AUTOSAR XML (schema 4-2-2)
package /APTIV_MODEL_APP/ComponentType
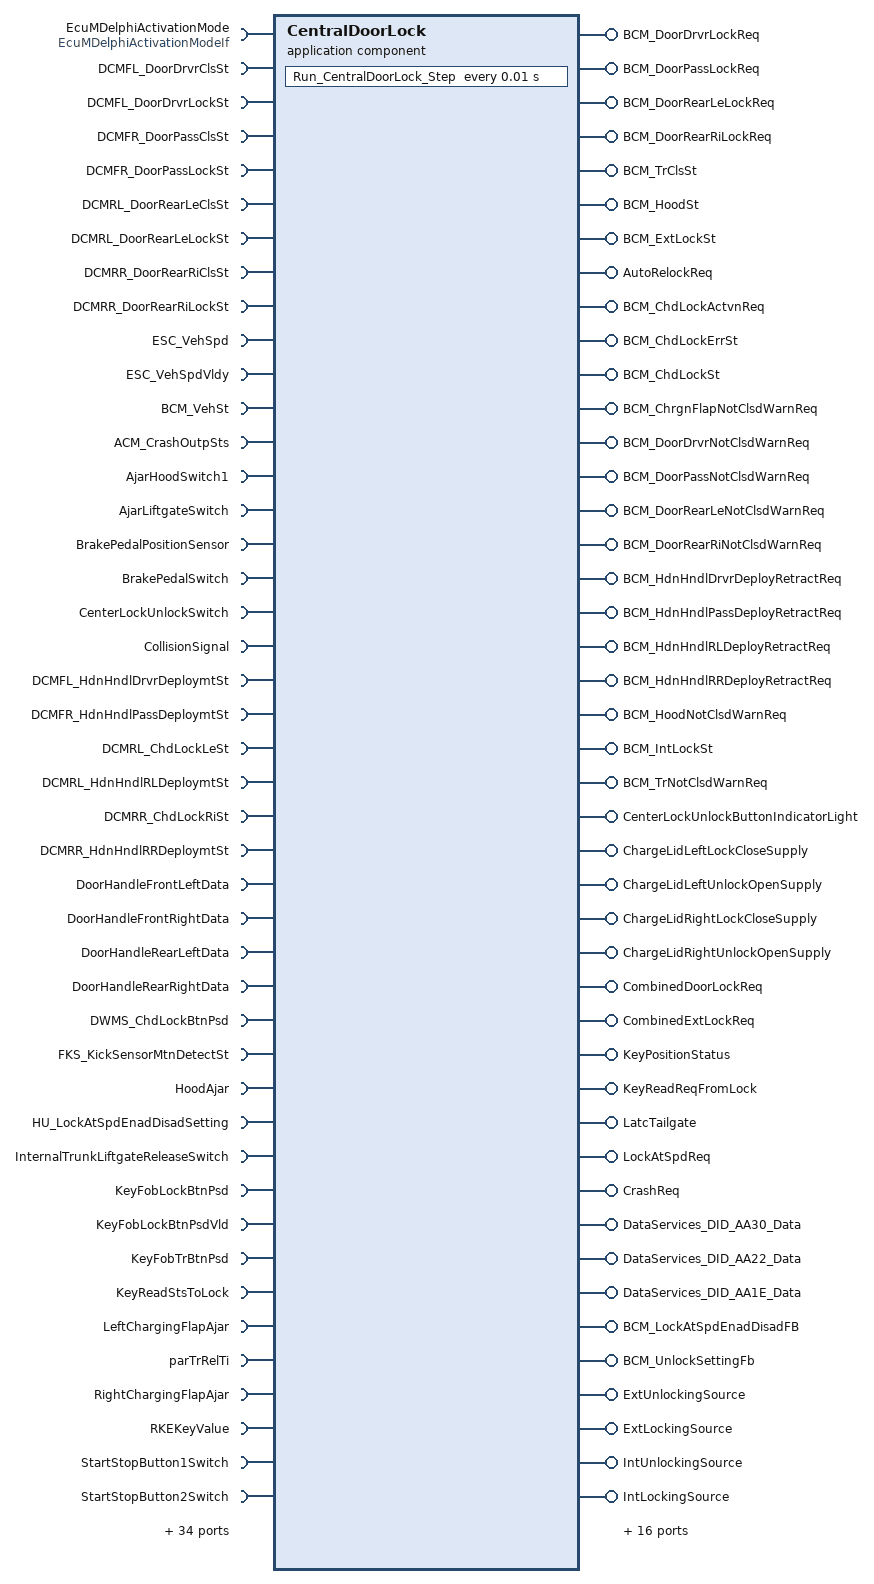
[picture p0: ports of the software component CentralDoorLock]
  application sw component type CentralDoorLock
    12 x require port:
      EcuMDelphiActivationMode: mode-switch-receiver-com-spec=supports-asynchronous-mode-switch=false, required-interface=EcuMDelphiActivationModeIf
      DCMFL_DoorDrvrClsSt: nonqueued-receiver-com-spec{data-element=DCMFL_DoorDrvrClsSt, init-value=constant-reference=Temp_InitValue}, required-interface=DCMFL_DoorDrvrClsSt
      DCMFL_DoorDrvrLockSt: nonqueued-receiver-com-spec{data-element=DCMFL_DoorDrvrLockSt, init-value=constant-reference=Temp_InitValue}, required-interface=DCMFL_DoorDrvrLockSt
      DCMFR_DoorPassClsSt: nonqueued-receiver-com-spec{data-element=DCMFR_DoorPassClsSt, init-value=constant-reference=Temp_InitValue}, required-interface=DCMFR_DoorPassClsSt
      DCMFR_DoorPassLockSt: nonqueued-receiver-com-spec{data-element=DCMFR_DoorPassLockSt, init-value=constant-reference=Temp_InitValue}, required-interface=DCMFR_DoorPassLockSt
      DCMRL_DoorRearLeClsSt: nonqueued-receiver-com-spec{data-element=DCMRL_DoorRearLeClsSt, init-value=constant-reference=Temp_InitValue}, required-interface=DCMRL_DoorRearLeClsSt
      DCMRL_DoorRearLeLockSt: nonqueued-receiver-com-spec{data-element=DCMRL_DoorRearLeLockSt, init-value=constant-reference=Temp_InitValue}, required-interface=DCMRL_DoorRearLeLockSt
      DCMRR_DoorRearRiClsSt: nonqueued-receiver-com-spec{data-element=DCMRR_DoorRearRiClsSt, init-value=constant-reference=Temp_InitValue}, required-interface=DCMRR_DoorRearRiClsSt
      DCMRR_DoorRearRiLockSt: nonqueued-receiver-com-spec{data-element=DCMRR_DoorRearRiLockSt, init-value=constant-reference=Temp_InitValue}, required-interface=DCMRR_DoorRearRiLockSt
      ESC_VehSpd: nonqueued-receiver-com-spec{data-element=ESC_VehSpd, init-value=constant-reference=Temp_InitValue}, required-interface=ESC_VehSpd
      ESC_VehSpdVldy: nonqueued-receiver-com-spec{data-element=ESC_VehSpdVldy, init-value=constant-reference=Temp_InitValue}, required-interface=ESC_VehSpdVldy
      BCM_VehSt: nonqueued-receiver-com-spec{data-element=BCM_VehSt, init-value=constant-reference=Temp_InitValue}, required-interface=BCM_VehSt
    7 x provide port:
      BCM_DoorDrvrLockReq: nonqueued-sender-com-spec{data-element=BCM_DoorDrvrLockReq, init-value=constant-reference=Temp_InitValue}, provided-interface=BCM_DoorDrvrLockReq
      BCM_DoorPassLockReq: nonqueued-sender-com-spec{data-element=BCM_DoorPassLockReq, init-value=constant-reference=Temp_InitValue}, provided-interface=BCM_DoorPassLockReq
      BCM_DoorRearLeLockReq: nonqueued-sender-com-spec{data-element=BCM_DoorRearLeLockReq, init-value=constant-reference=Temp_InitValue}, provided-interface=BCM_DoorRearLeLockReq
      BCM_DoorRearRiLockReq: nonqueued-sender-com-spec{data-element=BCM_DoorRearRiLockReq, init-value=constant-reference=Temp_InitValue}, provided-interface=BCM_DoorRearRiLockReq
      BCM_TrClsSt: nonqueued-sender-com-spec{data-element=BCM_TrClsSt, init-value=constant-reference=Temp_InitValue}, provided-interface=BCM_TrClsSt
      BCM_HoodSt: nonqueued-sender-com-spec{data-element=BCM_HoodSt, init-value=constant-reference=Temp_InitValue}, provided-interface=BCM_HoodSt
      BCM_ExtLockSt: nonqueued-sender-com-spec{data-element=BCM_ExtLockSt, init-value=constant-reference=Temp_InitValue}, provided-interface=BCM_ExtLockSt
    35 x require port:
      ACM_CrashOutpSts: nonqueued-receiver-com-spec{data-element=ACM_CrashOutpSts, init-value=constant-reference=Temp_InitValue}, required-interface=ACM_CrashOutpSts
      AjarHoodSwitch1: nonqueued-receiver-com-spec{data-element=AjarHoodSwitch1, init-value=constant-reference=Temp_InitValue}, required-interface=AjarHoodSwitch1
      AjarLiftgateSwitch: nonqueued-receiver-com-spec{data-element=AjarLiftgateSwitch, init-value=constant-reference=Temp_InitValue}, required-interface=AjarLiftgateSwitch
      BrakePedalPositionSensor: nonqueued-receiver-com-spec{data-element=BrakePedalPositionSensor, init-value=constant-reference=Temp_InitValue}, required-interface=BrakePedalPositionSensor
      BrakePedalSwitch: nonqueued-receiver-com-spec{data-element=BrakePedalSwitch, init-value=constant-reference=Temp_InitValue}, required-interface=BrakePedalSwitch
      CenterLockUnlockSwitch: nonqueued-receiver-com-spec{data-element=CenterLockUnlockSwitch, init-value=constant-reference=Temp_InitValue}, required-interface=CenterLockUnlockSwitch
      CollisionSignal: nonqueued-receiver-com-spec{data-element=CollisionSignal, init-value=constant-reference=Temp_InitValue}, required-interface=CollisionSignal
      DCMFL_HdnHndlDrvrDeploymtSt: nonqueued-receiver-com-spec{data-element=DCMFL_HdnHndlDrvrDeploymtSt, init-value=constant-reference=Temp_InitValue}, required-interface=DCMFL_HdnHndlDrvrDeploymtSt
      DCMFR_HdnHndlPassDeploymtSt: nonqueued-receiver-com-spec{data-element=DCMFR_HdnHndlPassDeploymtSt, init-value=constant-reference=Temp_InitValue}, required-interface=DCMFR_HdnHndlPassDeploymtSt
      DCMRL_ChdLockLeSt: nonqueued-receiver-com-spec{data-element=DCMRL_ChdLockLeSt, init-value=constant-reference=Temp_InitValue}, required-interface=DCMRL_ChdLockLeSt
      DCMRL_HdnHndlRLDeploymtSt: nonqueued-receiver-com-spec{data-element=DCMRL_HdnHndlRLDeploymtSt, init-value=constant-reference=Temp_InitValue}, required-interface=DCMRL_HdnHndlRLDeploymtSt
      DCMRR_ChdLockRiSt: nonqueued-receiver-com-spec{data-element=DCMRR_ChdLockRiSt, init-value=constant-reference=Temp_InitValue}, required-interface=DCMRR_ChdLockRiSt
      DCMRR_HdnHndlRRDeploymtSt: nonqueued-receiver-com-spec{data-element=DCMRR_HdnHndlRRDeploymtSt, init-value=constant-reference=Temp_InitValue}, required-interface=DCMRR_HdnHndlRRDeploymtSt
      DoorHandleFrontLeftData: nonqueued-receiver-com-spec{data-element=DoorHandleFrontLeftData, init-value=constant-reference=Temp_InitValue}, required-interface=DoorHandleFrontLeftData
      DoorHandleFrontRightData: nonqueued-receiver-com-spec{data-element=DoorHandleFrontRightData, init-value=constant-reference=Temp_InitValue}, required-interface=DoorHandleFrontRightData
      DoorHandleRearLeftData: nonqueued-receiver-com-spec{data-element=DoorHandleRearLeftData, init-value=constant-reference=Temp_InitValue}, required-interface=DoorHandleRearLeftData
      DoorHandleRearRightData: nonqueued-receiver-com-spec{data-element=DoorHandleRearRightData, init-value=constant-reference=Temp_InitValue}, required-interface=DoorHandleRearRightData
      DWMS_ChdLockBtnPsd: nonqueued-receiver-com-spec{data-element=DWMS_ChdLockBtnPsd, init-value=constant-reference=Temp_InitValue}, required-interface=DWMS_ChdLockBtnPsd
      FKS_KickSensorMtnDetectSt: nonqueued-receiver-com-spec{data-element=FKS_KickSensorMtnDetectSt, init-value=constant-reference=Temp_InitValue}, required-interface=FKS_KickSensorMtnDetectSt
      HoodAjar: nonqueued-receiver-com-spec{data-element=HoodAjar, init-value=constant-reference=Temp_InitValue}, required-interface=HoodAjar
      HU_LockAtSpdEnadDisadSetting: nonqueued-receiver-com-spec{data-element=HU_LockAtSpdEnadDisadSetting, enable-update=true, init-value=constant-reference=Temp_InitValue}, required-interface=HU_LockAtSpdEnadDisadSetting
      InternalTrunkLiftgateReleaseSwitch: nonqueued-receiver-com-spec{data-element=InternalTrunkLiftgateReleaseSwitch, init-value=constant-reference=Temp_InitValue}, required-interface=InternalTrunkLiftgateReleaseSwitch
      KeyFobLockBtnPsd: nonqueued-receiver-com-spec{data-element=KeyFobLockBtnPsd, init-value=constant-reference=Temp_InitValue}, required-interface=KeyFobLockBtnPsd
      KeyFobLockBtnPsdVld: nonqueued-receiver-com-spec{data-element=KeyFobLockBtnPsdVld, init-value=constant-reference=Temp_InitValue}, required-interface=KeyFobLockBtnPsdVld
      KeyFobTrBtnPsd: nonqueued-receiver-com-spec{data-element=KeyFobTrBtnPsd, init-value=constant-reference=Temp_InitValue}, required-interface=KeyFobTrBtnPsd
      KeyReadStsToLock: nonqueued-receiver-com-spec{data-element=KeyReadStsToLock, init-value=constant-reference=Temp_InitValue}, required-interface=KeyReadStsToLock
      LeftChargingFlapAjar: nonqueued-receiver-com-spec{data-element=LeftChargingFlapAjar, init-value=constant-reference=Temp_InitValue}, required-interface=LeftChargingFlapAjar
      parTrRelTi: nonqueued-receiver-com-spec{data-element=parTrRelTi, init-value=constant-reference=Temp_InitValue}, required-interface=parTrRelTi
      RightChargingFlapAjar: nonqueued-receiver-com-spec{data-element=RightChargingFlapAjar, init-value=constant-reference=Temp_InitValue}, required-interface=RightChargingFlapAjar
      RKEKeyValue: nonqueued-receiver-com-spec{data-element=RKEKeyValue, init-value=constant-reference=Temp_InitValue}, required-interface=RKEKeyValue
      StartStopButton1Switch: nonqueued-receiver-com-spec{data-element=StartStopButton1Switch, init-value=constant-reference=Temp_InitValue}, required-interface=StartStopButton1Switch
      StartStopButton2Switch: nonqueued-receiver-com-spec{data-element=StartStopButton2Switch, init-value=constant-reference=Temp_InitValue}, required-interface=StartStopButton2Switch
      TCM_TrClsSt_TCM: nonqueued-receiver-com-spec{data-element=TCM_TrClsSt_TCM, init-value=constant-reference=Temp_InitValue}, required-interface=TCM_TrClsSt_TCM
      TrunkReleaseSwitch: nonqueued-receiver-com-spec{data-element=TrunkReleaseSwitch, init-value=constant-reference=Temp_InitValue}, required-interface=TrunkReleaseSwitch
      VCU_LoglGearStsAct: nonqueued-receiver-com-spec{data-element=VCU_LoglGearStsAct, init-value=constant-reference=Temp_InitValue}, required-interface=VCU_LoglGearStsAct
    27 x provide port:
      AutoRelockReq: nonqueued-sender-com-spec{data-element=AutoRelockReq, init-value=constant-reference=Temp_InitValue}, provided-interface=AutoRelockReq
      BCM_ChdLockActvnReq: nonqueued-sender-com-spec{data-element=BCM_ChdLockActvnReq, init-value=constant-reference=Temp_InitValue}, provided-interface=BCM_ChdLockActvnReq
      BCM_ChdLockErrSt: nonqueued-sender-com-spec{data-element=BCM_ChdLockErrSt, init-value=constant-reference=Temp_InitValue}, provided-interface=BCM_ChdLockErrSt
      BCM_ChdLockSt: nonqueued-sender-com-spec{data-element=BCM_ChdLockSt, init-value=constant-reference=Temp_InitValue}, provided-interface=BCM_ChdLockSt
      BCM_ChrgnFlapNotClsdWarnReq: nonqueued-sender-com-spec{data-element=BCM_ChrgnFlapNotClsdWarnReq, init-value=constant-reference=Temp_InitValue}, provided-interface=BCM_ChrgnFlapNotClsdWarnReq
      BCM_DoorDrvrNotClsdWarnReq: nonqueued-sender-com-spec{data-element=BCM_DoorDrvrNotClsdWarnReq, init-value=constant-reference=Temp_InitValue}, provided-interface=BCM_DoorDrvrNotClsdWarnReq
      BCM_DoorPassNotClsdWarnReq: nonqueued-sender-com-spec{data-element=BCM_DoorPassNotClsdWarnReq, init-value=constant-reference=Temp_InitValue}, provided-interface=BCM_DoorPassNotClsdWarnReq
      BCM_DoorRearLeNotClsdWarnReq: nonqueued-sender-com-spec{data-element=BCM_DoorRearLeNotClsdWarnReq, init-value=constant-reference=Temp_InitValue}, provided-interface=BCM_DoorRearLeNotClsdWarnReq
      BCM_DoorRearRiNotClsdWarnReq: nonqueued-sender-com-spec{data-element=BCM_DoorRearRiNotClsdWarnReq, init-value=constant-reference=Temp_InitValue}, provided-interface=BCM_DoorRearRiNotClsdWarnReq
      BCM_HdnHndlDrvrDeployRetractReq: nonqueued-sender-com-spec{data-element=BCM_HdnHndlDrvrDeployRetractReq, init-value=constant-reference=Temp_InitValue}, provided-interface=BCM_HdnHndlDrvrDeployRetractReq
      BCM_HdnHndlPassDeployRetractReq: nonqueued-sender-com-spec{data-element=BCM_HdnHndlPassDeployRetractReq, init-value=constant-reference=Temp_InitValue}, provided-interface=BCM_HdnHndlPassDeployRetractReq
      BCM_HdnHndlRLDeployRetractReq: nonqueued-sender-com-spec{data-element=BCM_HdnHndlRLDeployRetractReq, init-value=constant-reference=Temp_InitValue}, provided-interface=BCM_HdnHndlRLDeployRetractReq
      BCM_HdnHndlRRDeployRetractReq: nonqueued-sender-com-spec{data-element=BCM_HdnHndlRRDeployRetractReq, init-value=constant-reference=Temp_InitValue}, provided-interface=BCM_HdnHndlRRDeployRetractReq
      BCM_HoodNotClsdWarnReq: nonqueued-sender-com-spec{data-element=BCM_HoodNotClsdWarnReq, init-value=constant-reference=Temp_InitValue}, provided-interface=BCM_HoodNotClsdWarnReq
      BCM_IntLockSt: nonqueued-sender-com-spec{data-element=BCM_IntLockSt, init-value=constant-reference=Temp_InitValue}, provided-interface=BCM_IntLockSt
      BCM_TrNotClsdWarnReq: nonqueued-sender-com-spec{data-element=BCM_TrNotClsdWarnReq, init-value=constant-reference=Temp_InitValue}, provided-interface=BCM_TrNotClsdWarnReq
      CenterLockUnlockButtonIndicatorLight: nonqueued-sender-com-spec{data-element=CenterLockUnlockButtonIndicatorLight, init-value=constant-reference=Temp_InitValue}, provided-interface=CenterLockUnlockButtonIndicatorLight
      ChargeLidLeftLockCloseSupply: nonqueued-sender-com-spec{data-element=ChargeLidLeftLockCloseSupply, init-value=constant-reference=Temp_InitValue}, provided-interface=ChargeLidLeftLockCloseSupply
      ChargeLidLeftUnlockOpenSupply: nonqueued-sender-com-spec{data-element=ChargeLidLeftUnlockOpenSupply, init-value=constant-reference=Temp_InitValue}, provided-interface=ChargeLidLeftUnlockOpenSupply
      ChargeLidRightLockCloseSupply: nonqueued-sender-com-spec{data-element=ChargeLidRightLockCloseSupply, init-value=constant-reference=Temp_InitValue}, provided-interface=ChargeLidRightLockCloseSupply
      ChargeLidRightUnlockOpenSupply: nonqueued-sender-com-spec{data-element=ChargeLidRightUnlockOpenSupply, init-value=constant-reference=Temp_InitValue}, provided-interface=ChargeLidRightUnlockOpenSupply
      CombinedDoorLockReq: nonqueued-sender-com-spec{data-element=CombinedDoorLockReq, init-value=constant-reference=Temp_InitValue}, provided-interface=CombinedDoorLockReq
      CombinedExtLockReq: nonqueued-sender-com-spec{data-element=CombinedExtLockReq, init-value=constant-reference=Temp_InitValue}, provided-interface=CombinedExtLockReq
      KeyPositionStatus: nonqueued-sender-com-spec{data-element=KeyPositionStatus, init-value=constant-reference=Temp_InitValue}, provided-interface=KeyPositionStatus
      KeyReadReqFromLock: nonqueued-sender-com-spec{data-element=KeyReadReqFromLock, init-value=constant-reference=Temp_InitValue}, provided-interface=KeyReadReqFromLock
      LatcTailgate: nonqueued-sender-com-spec{data-element=LatcTailgate, init-value=constant-reference=Temp_InitValue}, provided-interface=LatcTailgate
      LockAtSpdReq: nonqueued-sender-com-spec{data-element=LockAtSpdReq, init-value=constant-reference=Temp_InitValue}, provided-interface=LockAtSpdReq
    require port CarCfgIntDistbn: required-interface=CarCfgIntDistbn
      required-com-specs:
        data-element=CarCfg232, init-value=constant-reference=Temp_InitValue
        data-element=CarCfg238, init-value=constant-reference=Temp_InitValue
        data-element=CarCfg319, init-value=constant-reference=Temp_InitValue
        data-element=CarCfg326, init-value=constant-reference=Temp_InitValue
    4 x provide port:
      CrashReq: nonqueued-sender-com-spec{data-element=CrashReq, init-value=constant-reference=Temp_InitValue}, provided-interface=CrashReq
      DataServices_DID_AA30_Data: provided-interface=DataServices_DID_AA30_Data
      DataServices_DID_AA22_Data: provided-interface=DataServices_DID_AA22_Data
      DataServices_DID_AA1E_Data: provided-interface=DataServices_DID_AA1E_Data
    25 x require port:
      TBOX_CloudLockUnlckReq: nonqueued-receiver-com-spec{data-element=TBOX_CloudLockUnlckReq, init-value=constant-reference=Temp_InitValue}, required-interface=TBOX_CloudLockUnlckReq
      TBOX_MobileAppLockUlckDoorReq: nonqueued-receiver-com-spec{data-element=TBOX_MobileAppLockUlckDoorReq, init-value=constant-reference=Temp_InitValue}, required-interface=TBOX_MobileAppLockUlckDoorReq
      ACM_RollovrCrashOutpSts: nonqueued-receiver-com-spec{data-element=ACM_RollovrCrashOutpSts, init-value=constant-reference=Temp_InitValue}, required-interface=ACM_RollovrCrashOutpSts
      BMS_HVBattThermRunaway: nonqueued-receiver-com-spec{data-element=BMS_HVBattThermRunaway, init-value=constant-reference=Temp_InitValue}, required-interface=BMS_HVBattThermRunaway
      HU_UnlockSetting: nonqueued-receiver-com-spec{data-element=HU_UnlockSetting, init-value=constant-reference=Temp_InitValue}, required-interface=HU_UnlockSetting
      NFC_NFCCardOutsideAuthentSt: nonqueued-receiver-com-spec{data-element=NFC_NFCCardOutsideAuthentSt, init-value=constant-reference=Temp_InitValue}, required-interface=NFC_NFCCardOutsideAuthentSt
      NFC_NFCCardOutsideRequest: nonqueued-receiver-com-spec{data-element=NFC_NFCCardOutsideRequest, init-value=constant-reference=Temp_InitValue}, required-interface=NFC_NFCCardOutsideRequest
      NFC_ImobNFCKeyAuthentSt: nonqueued-receiver-com-spec{data-element=NFC_ImobNFCKeyAuthentSt, init-value=constant-reference=Temp_InitValue}, required-interface=NFC_ImobNFCKeyAuthentSt
      HU_DCChrgnFlapRelReq: nonqueued-receiver-com-spec{data-element=HU_DCChrgnFlapRelReq, init-value=constant-reference=Temp_InitValue}, required-interface=HU_DCChrgnFlapRelReq
      HU_ACChrgnFlapRelReq: nonqueued-receiver-com-spec{data-element=HU_ACChrgnFlapRelReq, init-value=constant-reference=Temp_InitValue}, required-interface=HU_ACChrgnFlapRelReq
      HU_ChdLockSetting: nonqueued-receiver-com-spec{data-element=HU_ChdLockSetting, init-value=constant-reference=Temp_InitValue}, required-interface=HU_ChdLockSetting
      HU_ElecTrMaxOpenPossetting: nonqueued-receiver-com-spec{data-element=HU_ElecTrMaxOpenPossetting, init-value=constant-reference=Temp_InitValue}, required-interface=HU_ElecTrMaxOpenPossetting
      TCM_ElecTrMaxOpenPos: nonqueued-receiver-com-spec{data-element=TCM_ElecTrMaxOpenPos, init-value=constant-reference=Temp_InitValue}, required-interface=TCM_ElecTrMaxOpenPos
      HU_PepsAutoUnlockActSt: nonqueued-receiver-com-spec{data-element=HU_PepsAutoUnlockActSt, init-value=constant-reference=Temp_InitValue}, required-interface=HU_PepsAutoUnlockActSt
      HU_AutEclClsCfg: nonqueued-receiver-com-spec{data-element=HU_AutEclClsCfg, init-value=constant-reference=Temp_InitValue}, required-interface=HU_AutEclClsCfg
      HU_LockIndicatorSetting: nonqueued-receiver-com-spec{data-element=HU_LockIndicatorSetting, init-value=constant-reference=Temp_InitValue}, required-interface=HU_LockIndicatorSetting
      HU_ElecTrunkReq: nonqueued-receiver-com-spec{data-element=HU_ElecTrunkReq, init-value=constant-reference=Temp_InitValue}, required-interface=HU_ElecTrunkReq
      BCM_VehSecuAlrmSysSt: nonqueued-receiver-com-spec{data-element=BCM_VehSecuAlrmSysSt, init-value=constant-reference=Temp_InitValue}, required-interface=BCM_VehSecuAlrmSysSt
      ECL_EclActualPosition: nonqueued-receiver-com-spec{data-element=ECL_EclActualPosition, init-value=constant-reference=Temp_InitValue}, required-interface=ECL_EclActualPosition
      TBOX_MobileAppOpenClsChrgnLidReq: nonqueued-receiver-com-spec{data-element=TBOX_MobileAppOpenClsChrgnLidReq, init-value=constant-reference=Temp_InitValue}, required-interface=TBOX_MobileAppOpenClsChrgnLidReq
      IPU_ChrgAcCnctrDetd: nonqueued-receiver-com-spec{data-element=IPU_ChrgAcCnctrDetd, init-value=constant-reference=Temp_InitValue}, required-interface=IPU_ChrgAcCnctrDetd
      BMS_ChrgDcCnctrDetd: nonqueued-receiver-com-spec{data-element=BMS_ChrgDcCnctrDetd, init-value=constant-reference=Temp_InitValue}, required-interface=BMS_ChrgDcCnctrDetd
      TBOX_MobileAppOpenClsTrunkReq: nonqueued-receiver-com-spec{data-element=TBOX_MobileAppOpenClsTrunkReq, init-value=constant-reference=Temp_InitValue}, required-interface=TBOX_MobileAppOpenClsTrunkReq
      NFC_NFCCardInsideAuthentSt: nonqueued-receiver-com-spec{data-element=NFC_NFCCardInsideAuthentSt, init-value=constant-reference=Temp_InitValue}, required-interface=NFC_NFCCardInsideAuthentSt
      NFC_NFCCardInsideRequest: nonqueued-receiver-com-spec{data-element=NFC_NFCCardInsideRequest, init-value=constant-reference=Temp_InitValue}, required-interface=NFC_NFCCardInsideRequest
    20 x provide port:
      BCM_LockAtSpdEnadDisadFB: nonqueued-sender-com-spec{data-element=BCM_LockAtSpdEnadDisadFB, init-value=constant-reference=Temp_InitValue}, provided-interface=BCM_LockAtSpdEnadDisadFB
      BCM_UnlockSettingFb: nonqueued-sender-com-spec{data-element=BCM_UnlockSettingFb, init-value=constant-reference=Temp_InitValue}, provided-interface=BCM_UnlockSettingFb
      ExtUnlockingSource: nonqueued-sender-com-spec{data-element=ExtUnlockingSource, init-value=constant-reference=Temp_InitValue}, provided-interface=ExtUnlockingSource
      ExtLockingSource: nonqueued-sender-com-spec{data-element=ExtLockingSource, init-value=constant-reference=Temp_InitValue}, provided-interface=ExtLockingSource
      IntUnlockingSource: nonqueued-sender-com-spec{data-element=IntUnlockingSource, init-value=constant-reference=Temp_InitValue}, provided-interface=IntUnlockingSource
      IntLockingSource: nonqueued-sender-com-spec{data-element=IntLockingSource, init-value=constant-reference=Temp_InitValue}, provided-interface=IntLockingSource
      BCM_KeyPositionStatus: nonqueued-sender-com-spec{data-element=BCM_KeyPositionStatus, init-value=constant-reference=Temp_InitValue}, provided-interface=BCM_KeyPositionStatus
      BCM_PepsAutoUnlockActStFB: nonqueued-sender-com-spec{data-element=BCM_PepsAutoUnlockActStFB, init-value=constant-reference=Temp_InitValue}, provided-interface=BCM_PepsAutoUnlockActStFB
      BCM_AutEclClsCfgFb: nonqueued-sender-com-spec{data-element=BCM_AutEclClsCfgFb, init-value=constant-reference=Temp_InitValue}, provided-interface=BCM_AutEclClsCfgFb
      BCM_LockIndicatorFb: nonqueued-sender-com-spec{data-element=BCM_LockIndicatorFb, init-value=constant-reference=Temp_InitValue}, provided-interface=BCM_LockIndicatorFb
      BCM_ChrgnFlapLeClsSt: nonqueued-sender-com-spec{data-element=BCM_ChrgnFlapLeClsSt, init-value=constant-reference=Temp_InitValue}, provided-interface=BCM_ChrgnFlapLeClsSt
      BCM_ChrgnFlapRiClsSt: nonqueued-sender-com-spec{data-element=BCM_ChrgnFlapRiClsSt, init-value=constant-reference=Temp_InitValue}, provided-interface=BCM_ChrgnFlapRiClsSt
      BCM_EclBeReqToTagetPos: nonqueued-sender-com-spec{data-element=BCM_EclBeReqToTagetPos, init-value=constant-reference=Temp_InitValue}, provided-interface=BCM_EclBeReqToTagetPos
      PEtrunk: nonqueued-sender-com-spec{data-element=PEtrunk, init-value=constant-reference=Temp_InitValue}, provided-interface=PEtrunk
      BCM_TrOpenerReqTrigSrc: nonqueued-sender-com-spec{data-element=BCM_TrOpenerReqTrigSrc, init-value=constant-reference=Temp_InitValue}, provided-interface=BCM_TrOpenerReqTrigSrc
      BCM_ElecTrOpenCls: nonqueued-sender-com-spec{data-element=BCM_ElecTrOpenCls, init-value=constant-reference=Temp_InitValue}, provided-interface=BCM_ElecTrOpenCls
      BCM_KickSensorEnablerCmd: nonqueued-sender-com-spec{data-element=BCM_KickSensorEnablerCmd, init-value=constant-reference=Temp_InitValue}, provided-interface=BCM_KickSensorEnablerCmd
      WarningFromLock: nonqueued-sender-com-spec{data-element=WarningFromLock, init-value=constant-reference=Temp_InitValue}, provided-interface=WarningFromLock
      BCM_ChrgnFlapRiNotClsdWarnReq: nonqueued-sender-com-spec{data-element=BCM_ChrgnFlapRiNotClsdWarnReq, init-value=constant-reference=Temp_InitValue}, provided-interface=BCM_ChrgnFlapRiNotClsdWarnReq
      BCM_BLELocalizationReq: nonqueued-sender-com-spec{data-element=BCM_BLELocalizationReq, init-value=constant-reference=Temp_InitValue}, provided-interface=BCM_BLELocalizationReq
    require port TBOX_BLEConStatus: nonqueued-receiver-com-spec{data-element=TBOX_BLEConStatus, init-value=constant-reference=Temp_InitValue}, required-interface=TBOX_BLEConStatus
    require port TBOX_BLELocalizationSts: nonqueued-receiver-com-spec{data-element=TBOX_BLELocalizationSts, init-value=constant-reference=Temp_InitValue}, required-interface=TBOX_BLELocalizationSts
    require port ESC_BrkPedlSts: nonqueued-receiver-com-spec{data-element=ESC_BrkPedlSts, init-value=constant-reference=Temp_InitValue}, required-interface=ESC_BrkPedlSts
    provide port Pskeyincar: nonqueued-sender-com-spec{data-element=Pskeyincar, init-value=constant-reference=Temp_InitValue}, provided-interface=Pskeyincar
    require port Event_EV_DTC_E11F87: required-interface=DiagnosticMonitor
    require port OpMode: nonqueued-receiver-com-spec{data-element=OpMode, init-value=constant-reference=Temp_InitValue}, required-interface=OpMode
    provide port CentralDoorLockLIN8WkpReq: nonqueued-sender-com-spec{data-element=CentralDoorLockLIN8WkpReq, init-value=constant-reference=Temp_InitValue}, provided-interface=CentralDoorLockLIN8WkpReq
    behavior IBCentralDoorLock: data-type-mapping=[DataTypeMappingSet, DataTypeMappingSetIntMod, Mode_DataTMappingSet_Delphi], handle-termination-and-restart=NO-SUPPORT
      ar-typed-per-instance-memorys:
        data CentralDoorLockNvAlias: type=CentralDoorLockNvStruct
      swc mode switch event CentralDoorLockInitEv: start-on-event=Run_CentralDoorLock_Init, activation=ON-ENTRY, mode=EcuMDelphiActivationMode.EcuMDelphiActivationMode.DELPHI_ACTIVE
      timing event CentralDoorLockStep: disabled-mode=EcuMDelphiActivationMode.EcuMDelphiActivationMode.DELPHI_NOT_ACTIVE, start-on-event=Run_CentralDoorLock_Step, period=0.01
      12 x operation invoked event:
        OpInvokedEv_CentralDoorLock_DataServices_DID_AA30_Data_ReadData: start-on-event=CentralDoorLock_DataServices_DID_AA30_Data_ReadData, operation=DataServices_DID_AA30_Data.ReadData
        OpInvokedEv_DataServices_DID_AA30_Data_ConditionCheckRead: start-on-event=CentralDoorLock_DataServices_DID_AA30_Data_ConditionCheckRead, operation=DataServices_DID_AA30_Data.ConditionCheckRead
        OpInvokedEv_DataServices_DID_AA30_Data_ReturnControlToECU: start-on-event=CentralDoorLock_DataServices_DID_AA30_Data_ReturnControlToECU, operation=DataServices_DID_AA30_Data.ReturnControlToECU
        OpInvokedEv_DataServices_DID_AA30_Data_ShortTermAdjustment: start-on-event=CentralDoorLock_DataServices_DID_AA30_Data_ShortTermAdjustment, operation=DataServices_DID_AA30_Data.ShortTermAdjustment
        OpInvokedEv_DataServices_DID_AA22_Data_ConditionCheckRead: start-on-event=CentralDoorLock_DataServices_DID_AA22_Data_ConditionCheckRead, operation=DataServices_DID_AA22_Data.ConditionCheckRead
        OpInvokedEv_DataServices_DID_AA22_Data_ReadData: start-on-event=CentralDoorLock_DataServices_DID_AA22_Data_ReadData, operation=DataServices_DID_AA22_Data.ReadData
        OpInvokedEv_DataServices_DID_AA22_Data_ReturnControlToECU: start-on-event=CentralDoorLock_DataServices_DID_AA22_Data_ReturnControlToECU, operation=DataServices_DID_AA22_Data.ReturnControlToECU
        OpInvokedEv_DataServices_DID_AA22_Data_ShortTermAdjustment: start-on-event=CentralDoorLock_DataServices_DID_AA22_Data_ShortTermAdjustment, operation=DataServices_DID_AA22_Data.ShortTermAdjustment
        OpInvokedEv_DataServices_DID_AA1E_Data_ConditionCheckRead: start-on-event=CentralDoorLock_DataServices_DID_AA1E_Data_ConditionCheckRead, operation=DataServices_DID_AA1E_Data.ConditionCheckRead
        OpInvokedEv_DataServices_DID_AA1E_Data_ReturnControlToECU: start-on-event=CentralDoorLock_DataServices_DID_AA1E_Data_ReturnControlToECU, operation=DataServices_DID_AA1E_Data.ReturnControlToECU
        OpInvokedEv_DataServices_DID_AA1E_Data_ShortTermAdjustment: start-on-event=CentralDoorLock_DataServices_DID_AA1E_Data_ShortTermAdjustment, operation=DataServices_DID_AA1E_Data.ShortTermAdjustment
        OpInvokedEv_DataServices_DID_AA1E_Data_ReadData: start-on-event=CentralDoorLock_DataServices_DID_AA1E_Data_ReadData, operation=DataServices_DID_AA1E_Data.ReadData
      15 x runnable:
        Run_CentralDoorLock_Init: sw-addr-method=APTIV_RUN
        Run_CentralDoorLock_Step: sw-addr-method=APTIV_RUN
          data-receive-point-by-arguments:
            85 x access:
              ArgRecPoint_ACM_CrashOutpSts_ACM_CrashOutpSts: accessed-variable=ACM_CrashOutpSts.ACM_CrashOutpSts
              ArgRecPoint_AjarHoodSwitch1_AjarHoodSwitch1: accessed-variable=AjarHoodSwitch1.AjarHoodSwitch1
              ArgRecPoint_AjarLiftgateSwitch_AjarLiftgateSwitch: accessed-variable=AjarLiftgateSwitch.AjarLiftgateSwitch
              ArgRecPoint_BCM_VehSt_BCM_VehSt: accessed-variable=BCM_VehSt.BCM_VehSt
              ArgRecPoint_BrakePedalPositionSensor_BrakePedalPositionSensor: accessed-variable=BrakePedalPositionSensor.BrakePedalPositionSensor
              ArgRecPoint_BrakePedalSwitch_BrakePedalSwitch: accessed-variable=BrakePedalSwitch.BrakePedalSwitch
              ArgRecPoint_CarCfgIntDistbn_CarCfg232: accessed-variable=CarCfgIntDistbn.CarCfg232
              ArgRecPoint_CarCfgIntDistbn_CarCfg238: accessed-variable=CarCfgIntDistbn.CarCfg238
              ArgRecPoint_CarCfgIntDistbn_CarCfg319: accessed-variable=CarCfgIntDistbn.CarCfg319
              ArgRecPoint_CarCfgIntDistbn_CarCfg326: accessed-variable=CarCfgIntDistbn.CarCfg326
              ArgRecPoint_CenterLockUnlockSwitch_CenterLockUnlockSwitch: accessed-variable=CenterLockUnlockSwitch.CenterLockUnlockSwitch
              ArgRecPoint_CollisionSignal_CollisionSignal: accessed-variable=CollisionSignal.CollisionSignal
              ArgRecPoint_DCMFL_DoorDrvrClsSt_DCMFL_DoorDrvrClsSt: accessed-variable=DCMFL_DoorDrvrClsSt.DCMFL_DoorDrvrClsSt
              ArgRecPoint_DCMFL_DoorDrvrLockSt_DCMFL_DoorDrvrLockSt: accessed-variable=DCMFL_DoorDrvrLockSt.DCMFL_DoorDrvrLockSt
              ArgRecPoint_DCMFL_HdnHndlDrvrDeploymtSt_DCMFL_HdnHndlDrvrDeploymtSt: accessed-variable=DCMFL_HdnHndlDrvrDeploymtSt.DCMFL_HdnHndlDrvrDeploymtSt
              ArgRecPoint_DCMFR_DoorPassClsSt_DCMFR_DoorPassClsSt: accessed-variable=DCMFR_DoorPassClsSt.DCMFR_DoorPassClsSt
              ArgRecPoint_DCMFR_DoorPassLockSt_DCMFR_DoorPassLockSt: accessed-variable=DCMFR_DoorPassLockSt.DCMFR_DoorPassLockSt
              ArgRecPoint_DCMFR_HdnHndlPassDeploymtSt_DCMFR_HdnHndlPassDeploymtSt: accessed-variable=DCMFR_HdnHndlPassDeploymtSt.DCMFR_HdnHndlPassDeploymtSt
              ArgRecPoint_DCMRL_ChdLockLeSt_DCMRL_ChdLockLeSt: accessed-variable=DCMRL_ChdLockLeSt.DCMRL_ChdLockLeSt
              ArgRecPoint_DCMRL_DoorRearLeClsSt_DCMRL_DoorRearLeClsSt: accessed-variable=DCMRL_DoorRearLeClsSt.DCMRL_DoorRearLeClsSt
              ArgRecPoint_DCMRL_DoorRearLeLockSt_DCMRL_DoorRearLeLockSt: accessed-variable=DCMRL_DoorRearLeLockSt.DCMRL_DoorRearLeLockSt
              ArgRecPoint_DCMRL_HdnHndlRLDeploymtSt_DCMRL_HdnHndlRLDeploymtSt: accessed-variable=DCMRL_HdnHndlRLDeploymtSt.DCMRL_HdnHndlRLDeploymtSt
              ArgRecPoint_DCMRR_ChdLockRiSt_DCMRR_ChdLockRiSt: accessed-variable=DCMRR_ChdLockRiSt.DCMRR_ChdLockRiSt
              ArgRecPoint_DCMRR_DoorRearRiClsSt_DCMRR_DoorRearRiClsSt: accessed-variable=DCMRR_DoorRearRiClsSt.DCMRR_DoorRearRiClsSt
              ArgRecPoint_DCMRR_DoorRearRiLockSt_DCMRR_DoorRearRiLockSt: accessed-variable=DCMRR_DoorRearRiLockSt.DCMRR_DoorRearRiLockSt
              ArgRecPoint_DCMRR_HdnHndlRRDeploymtSt_DCMRR_HdnHndlRRDeploymtSt: accessed-variable=DCMRR_HdnHndlRRDeploymtSt.DCMRR_HdnHndlRRDeploymtSt
              ArgRecPoint_DoorHandleFrontLeftData_DoorHandleFrontLeftData: accessed-variable=DoorHandleFrontLeftData.DoorHandleFrontLeftData
              ArgRecPoint_DoorHandleFrontRightData_DoorHandleFrontRightData: accessed-variable=DoorHandleFrontRightData.DoorHandleFrontRightData
              ArgRecPoint_DoorHandleRearLeftData_DoorHandleRearLeftData: accessed-variable=DoorHandleRearLeftData.DoorHandleRearLeftData
              ArgRecPoint_DoorHandleRearRightData_DoorHandleRearRightData: accessed-variable=DoorHandleRearRightData.DoorHandleRearRightData
              ArgRecPoint_DWMS_ChdLockBtnPsd_DWMS_ChdLockBtnPsd: accessed-variable=DWMS_ChdLockBtnPsd.DWMS_ChdLockBtnPsd
              ArgRecPoint_ESC_VehSpd_ESC_VehSpd: accessed-variable=ESC_VehSpd.ESC_VehSpd
              ArgRecPoint_ESC_VehSpdVldy_ESC_VehSpdVldy: accessed-variable=ESC_VehSpdVldy.ESC_VehSpdVldy
              ArgRecPoint_FKS_KickSensorMtnDetectSt_FKS_KickSensorMtnDetectSt: accessed-variable=FKS_KickSensorMtnDetectSt.FKS_KickSensorMtnDetectSt
              ArgRecPoint_HoodAjar_HoodAjar: accessed-variable=HoodAjar.HoodAjar
              ArgRecPoint_HU_LockAtSpdEnadDisadSetting_HU_LockAtSpdEnadDisadSetting: accessed-variable=HU_LockAtSpdEnadDisadSetting.HU_LockAtSpdEnadDisadSetting
              ArgRecPoint_InternalTrunkLiftgateReleaseSwitch_InternalTrunkLiftgateReleaseSwitch: accessed-variable=InternalTrunkLiftgateReleaseSwitch.InternalTrunkLiftgateReleaseSwitch
              ArgRecPoint_KeyFobLockBtnPsd_KeyFobLockBtnPsd: accessed-variable=KeyFobLockBtnPsd.KeyFobLockBtnPsd
              ArgRecPoint_KeyFobLockBtnPsdVld_KeyFobLockBtnPsdVld: accessed-variable=KeyFobLockBtnPsdVld.KeyFobLockBtnPsdVld
              ArgRecPoint_KeyFobTrBtnPsd_KeyFobTrBtnPsd: accessed-variable=KeyFobTrBtnPsd.KeyFobTrBtnPsd
              ArgRecPoint_KeyReadStsToLock_KeyReadStsToLock: accessed-variable=KeyReadStsToLock.KeyReadStsToLock
              ArgRecPoint_LeftChargingFlapAjar_LeftChargingFlapAjar: accessed-variable=LeftChargingFlapAjar.LeftChargingFlapAjar
              ArgRecPoint_parTrRelTi_parTrRelTi: accessed-variable=parTrRelTi.parTrRelTi
              ArgRecPoint_RightChargingFlapAjar_RightChargingFlapAjar: accessed-variable=RightChargingFlapAjar.RightChargingFlapAjar
              ArgRecPoint_RKEKeyValue_RKEKeyValue: accessed-variable=RKEKeyValue.RKEKeyValue
              ArgRecPoint_StartStopButton1Switch_StartStopButton1Switch: accessed-variable=StartStopButton1Switch.StartStopButton1Switch
              ArgRecPoint_StartStopButton2Switch_StartStopButton2Switch: accessed-variable=StartStopButton2Switch.StartStopButton2Switch
              ArgRecPoint_TCM_TrClsSt_TCM_TCM_TrClsSt_TCM: accessed-variable=TCM_TrClsSt_TCM.TCM_TrClsSt_TCM
              ArgRecPoint_TrunkReleaseSwitch_TrunkReleaseSwitch: accessed-variable=TrunkReleaseSwitch.TrunkReleaseSwitch
              ArgRecPoint_VCU_LoglGearStsAct_VCU_LoglGearStsAct: accessed-variable=VCU_LoglGearStsAct.VCU_LoglGearStsAct
              ArgRecPoint_ACM_RollovrCrashOutpSts_ACM_RollovrCrashOutpSts: accessed-variable=ACM_RollovrCrashOutpSts.ACM_RollovrCrashOutpSts
              ArgRecPoint_TBOX_CloudLockUnlckReq_TBOX_CloudLockUnlckReq: accessed-variable=TBOX_CloudLockUnlckReq.TBOX_CloudLockUnlckReq
              ArgRecPoint_TBOX_MobileAppLockUlckDoorReq_TBOX_MobileAppLockUlckDoorReq: accessed-variable=TBOX_MobileAppLockUlckDoorReq.TBOX_MobileAppLockUlckDoorReq
              ArgRecPoint_BMS_HVBattThermRunaway_BMS_HVBattThermRunaway: accessed-variable=BMS_HVBattThermRunaway.BMS_HVBattThermRunaway
              ArgRecPoint_HU_UnlockSetting_HU_UnlockSetting: accessed-variable=HU_UnlockSetting.HU_UnlockSetting
              ArgRecPoint_NFC_NFCCardOutsideAuthentSt_NFC_NFCCardOutsideAuthentSt: accessed-variable=NFC_NFCCardOutsideAuthentSt.NFC_NFCCardOutsideAuthentSt
              ArgRecPoint_NFC_NFCCardOutsideRequest_NFC_NFCCardOutsideRequest: accessed-variable=NFC_NFCCardOutsideRequest.NFC_NFCCardOutsideRequest
              ArgRecPoint_NFC_ImobNFCKeyAuthentSt_NFC_ImobNFCKeyAuthentSt: accessed-variable=NFC_ImobNFCKeyAuthentSt.NFC_ImobNFCKeyAuthentSt
              ArgRecPoint_TBOX_BLEConStatus_TBOX_BLEConStatus: accessed-variable=TBOX_BLEConStatus.TBOX_BLEConStatus
              ArgRecPoint_TBOX_BLELocalizationSts_TBOX_BLELocalizationSts: accessed-variable=TBOX_BLELocalizationSts.TBOX_BLELocalizationSts
              ArgRecPoint_HU_DCChrgnFlapRelReq_HU_DCChrgnFlapRelReq: accessed-variable=HU_DCChrgnFlapRelReq.HU_DCChrgnFlapRelReq
              ArgRecPoint_HU_ACChrgnFlapRelReq_HU_ACChrgnFlapRelReq: accessed-variable=HU_ACChrgnFlapRelReq.HU_ACChrgnFlapRelReq
              ArgRecPoint_HU_ChdLockSetting_HU_ChdLockSetting: accessed-variable=HU_ChdLockSetting.HU_ChdLockSetting
              ArgRecPoint_HU_ElecTrMaxOpenPossetting_HU_ElecTrMaxOpenPossetting: accessed-variable=HU_ElecTrMaxOpenPossetting.HU_ElecTrMaxOpenPossetting
              ArgRecPoint_TCM_ElecTrMaxOpenPos_TCM_ElecTrMaxOpenPos: accessed-variable=TCM_ElecTrMaxOpenPos.TCM_ElecTrMaxOpenPos
              ArgRecPoint_HU_PepsAutoUnlockActSt_HU_PepsAutoUnlockActSt: accessed-variable=HU_PepsAutoUnlockActSt.HU_PepsAutoUnlockActSt
              ArgRecPoint_HU_AutEclClsCfg_HU_AutEclClsCfg: accessed-variable=HU_AutEclClsCfg.HU_AutEclClsCfg
              ArgRecPoint_HU_LockIndicatorSetting_HU_LockIndicatorSetting: accessed-variable=HU_LockIndicatorSetting.HU_LockIndicatorSetting
              ArgRecPoint_HU_ElecTrunkReq_HU_ElecTrunkReq: accessed-variable=HU_ElecTrunkReq.HU_ElecTrunkReq
              ArgRecPoint_BCM_VehSecuAlrmSysSt_BCM_VehSecuAlrmSysSt: accessed-variable=BCM_VehSecuAlrmSysSt.BCM_VehSecuAlrmSysSt
              ArgRecPoint_ECL_EclActualPosition_ECL_EclActualPosition: accessed-variable=ECL_EclActualPosition.ECL_EclActualPosition
              ArgRecPoint_TBOX_MobileAppOpenClsChrgnLidReq_TBOX_MobileAppOpenClsChrgnLidReq: accessed-variable=TBOX_MobileAppOpenClsChrgnLidReq.TBOX_MobileAppOpenClsChrgnLidReq
              ArgRecPoint_IPU_ChrgAcCnctrDetd_IPU_ChrgAcCnctrDetd: accessed-variable=IPU_ChrgAcCnctrDetd.IPU_ChrgAcCnctrDetd
              ArgRecPoint_BMS_ChrgDcCnctrDetd_BMS_ChrgDcCnctrDetd: accessed-variable=BMS_ChrgDcCnctrDetd.BMS_ChrgDcCnctrDetd
              ArgRecPoint_TBOX_MobileAppOpenClsTrunkReq_TBOX_MobileAppOpenClsTrunkReq: accessed-variable=TBOX_MobileAppOpenClsTrunkReq.TBOX_MobileAppOpenClsTrunkReq
              ArgRecPoint_NFC_NFCCardInsideAuthentSt_NFC_NFCCardInsideAuthentSt: accessed-variable=NFC_NFCCardInsideAuthentSt.NFC_NFCCardInsideAuthentSt
              ArgRecPoint_NFC_NFCCardInsideRequest_NFC_NFCCardInsideRequest: accessed-variable=NFC_NFCCardInsideRequest.NFC_NFCCardInsideRequest
              ArgRecPoint_CarCfgIntDistbn_CarCfg4: accessed-variable=CarCfgIntDistbn.CarCfg4
              ArgRecPoint_CarCfgIntDistbn_CarCfg251: accessed-variable=CarCfgIntDistbn.CarCfg251
              ArgRecPoint_CarCfgIntDistbn_CarCfg237: accessed-variable=CarCfgIntDistbn.CarCfg237
              ArgRecPoint_CarCfgIntDistbn_CarCfg236: accessed-variable=CarCfgIntDistbn.CarCfg236
              ArgRecPoint_CarCfgIntDistbn_CarCfg318: accessed-variable=CarCfgIntDistbn.CarCfg318
              ArgRecPoint_CarCfgIntDistbn_CarCfg320: accessed-variable=CarCfgIntDistbn.CarCfg320
              ArgRecPoint_ESC_BrkPedlSts_ESC_BrkPedlSts: accessed-variable=ESC_BrkPedlSts.ESC_BrkPedlSts
              ArgRecPoint_OpMode_OpMode: accessed-variable=OpMode.OpMode
          data-send-points:
            57 x access:
              SendPoint_AutoRelockReq_AutoRelockReq: accessed-variable=AutoRelockReq.AutoRelockReq
              SendPoint_BCM_ChdLockActvnReq_BCM_ChdLockActvnReq: accessed-variable=BCM_ChdLockActvnReq.BCM_ChdLockActvnReq
              SendPoint_BCM_ChdLockErrSt_BCM_ChdLockErrSt: accessed-variable=BCM_ChdLockErrSt.BCM_ChdLockErrSt
              SendPoint_BCM_ChdLockSt_BCM_ChdLockSt: accessed-variable=BCM_ChdLockSt.BCM_ChdLockSt
              SendPoint_BCM_ChrgnFlapNotClsdWarnReq_BCM_ChrgnFlapNotClsdWarnReq: accessed-variable=BCM_ChrgnFlapNotClsdWarnReq.BCM_ChrgnFlapNotClsdWarnReq
              SendPoint_BCM_DoorDrvrLockReq_BCM_DoorDrvrLockReq: accessed-variable=BCM_DoorDrvrLockReq.BCM_DoorDrvrLockReq
              SendPoint_BCM_DoorDrvrNotClsdWarnReq_BCM_DoorDrvrNotClsdWarnReq: accessed-variable=BCM_DoorDrvrNotClsdWarnReq.BCM_DoorDrvrNotClsdWarnReq
              SendPoint_BCM_DoorPassLockReq_BCM_DoorPassLockReq: accessed-variable=BCM_DoorPassLockReq.BCM_DoorPassLockReq
              SendPoint_BCM_DoorPassNotClsdWarnReq_BCM_DoorPassNotClsdWarnReq: accessed-variable=BCM_DoorPassNotClsdWarnReq.BCM_DoorPassNotClsdWarnReq
              SendPoint_BCM_DoorRearLeLockReq_BCM_DoorRearLeLockReq: accessed-variable=BCM_DoorRearLeLockReq.BCM_DoorRearLeLockReq
              SendPoint_BCM_DoorRearLeNotClsdWarnReq_BCM_DoorRearLeNotClsdWarnReq: accessed-variable=BCM_DoorRearLeNotClsdWarnReq.BCM_DoorRearLeNotClsdWarnReq
              SendPoint_BCM_DoorRearRiLockReq_BCM_DoorRearRiLockReq: accessed-variable=BCM_DoorRearRiLockReq.BCM_DoorRearRiLockReq
              SendPoint_BCM_DoorRearRiNotClsdWarnReq_BCM_DoorRearRiNotClsdWarnReq: accessed-variable=BCM_DoorRearRiNotClsdWarnReq.BCM_DoorRearRiNotClsdWarnReq
              SendPoint_BCM_ExtLockSt_BCM_ExtLockSt: accessed-variable=BCM_ExtLockSt.BCM_ExtLockSt
              SendPoint_BCM_HdnHndlDrvrDeployRetractReq_BCM_HdnHndlDrvrDeployRetractReq: accessed-variable=BCM_HdnHndlDrvrDeployRetractReq.BCM_HdnHndlDrvrDeployRetractReq
              SendPoint_BCM_HdnHndlPassDeployRetractReq_BCM_HdnHndlPassDeployRetractReq: accessed-variable=BCM_HdnHndlPassDeployRetractReq.BCM_HdnHndlPassDeployRetractReq
              SendPoint_BCM_HdnHndlRLDeployRetractReq_BCM_HdnHndlRLDeployRetractReq: accessed-variable=BCM_HdnHndlRLDeployRetractReq.BCM_HdnHndlRLDeployRetractReq
              SendPoint_BCM_HdnHndlRRDeployRetractReq_BCM_HdnHndlRRDeployRetractReq: accessed-variable=BCM_HdnHndlRRDeployRetractReq.BCM_HdnHndlRRDeployRetractReq
              SendPoint_BCM_HoodNotClsdWarnReq_BCM_HoodNotClsdWarnReq: accessed-variable=BCM_HoodNotClsdWarnReq.BCM_HoodNotClsdWarnReq
              SendPoint_BCM_HoodSt_BCM_HoodSt: accessed-variable=BCM_HoodSt.BCM_HoodSt
              SendPoint_BCM_IntLockSt_BCM_IntLockSt: accessed-variable=BCM_IntLockSt.BCM_IntLockSt
              SendPoint_BCM_TrClsSt_BCM_TrClsSt: accessed-variable=BCM_TrClsSt.BCM_TrClsSt
              SendPoint_BCM_TrNotClsdWarnReq_BCM_TrNotClsdWarnReq: accessed-variable=BCM_TrNotClsdWarnReq.BCM_TrNotClsdWarnReq
              SendPoint_CenterLockUnlockButtonIndicatorLight_CenterLockUnlockButtonIndicatorLight: accessed-variable=CenterLockUnlockButtonIndicatorLight.CenterLockUnlockButtonIndicatorLight
              SendPoint_ChargeLidLeftLockCloseSupply_ChargeLidLeftLockCloseSupply: accessed-variable=ChargeLidLeftLockCloseSupply.ChargeLidLeftLockCloseSupply
              SendPoint_ChargeLidLeftUnlockOpenSupply_ChargeLidLeftUnlockOpenSupply: accessed-variable=ChargeLidLeftUnlockOpenSupply.ChargeLidLeftUnlockOpenSupply
              SendPoint_ChargeLidRightLockCloseSupply_ChargeLidRightLockCloseSupply: accessed-variable=ChargeLidRightLockCloseSupply.ChargeLidRightLockCloseSupply
              SendPoint_ChargeLidRightUnlockOpenSupply_ChargeLidRightUnlockOpenSupply: accessed-variable=ChargeLidRightUnlockOpenSupply.ChargeLidRightUnlockOpenSupply
              SendPoint_CombinedDoorLockReq_CombinedDoorLockReq: accessed-variable=CombinedDoorLockReq.CombinedDoorLockReq
              SendPoint_CombinedExtLockReq_CombinedExtLockReq: accessed-variable=CombinedExtLockReq.CombinedExtLockReq
              SendPoint_KeyPositionStatus_KeyPositionStatus: accessed-variable=KeyPositionStatus.KeyPositionStatus
              SendPoint_KeyReadReqFromLock_KeyReadReqFromLock: accessed-variable=KeyReadReqFromLock.KeyReadReqFromLock
              SendPoint_LatcTailgate_LatcTailgate: accessed-variable=LatcTailgate.LatcTailgate
              SendPoint_LockAtSpdReq_LockAtSpdReq: accessed-variable=LockAtSpdReq.LockAtSpdReq
              SendPoint_CrashReq_CrashReq: accessed-variable=CrashReq.CrashReq
              SendPoint_BCM_LockAtSpdEnadDisadFB_BCM_LockAtSpdEnadDisadFB: accessed-variable=BCM_LockAtSpdEnadDisadFB.BCM_LockAtSpdEnadDisadFB
              SendPoint_BCM_UnlockSettingFb_BCM_UnlockSettingFb: accessed-variable=BCM_UnlockSettingFb.BCM_UnlockSettingFb
              SendPoint_ExtLockingSource_ExtLockingSource: accessed-variable=ExtLockingSource.ExtLockingSource
              SendPoint_ExtUnlockingSource_ExtUnlockingSource: accessed-variable=ExtUnlockingSource.ExtUnlockingSource
              SendPoint_IntLockingSource_IntLockingSource: accessed-variable=IntLockingSource.IntLockingSource
              SendPoint_IntUnlockingSource_IntUnlockingSource: accessed-variable=IntUnlockingSource.IntUnlockingSource
              SendPoint_BCM_KeyPositionStatus_BCM_KeyPositionStatus: accessed-variable=BCM_KeyPositionStatus.BCM_KeyPositionStatus
              SendPoint_BCM_PepsAutoUnlockActStFB_BCM_PepsAutoUnlockActStFB: accessed-variable=BCM_PepsAutoUnlockActStFB.BCM_PepsAutoUnlockActStFB
              SendPoint_BCM_AutEclClsCfgFb_BCM_AutEclClsCfgFb: accessed-variable=BCM_AutEclClsCfgFb.BCM_AutEclClsCfgFb
              SendPoint_BCM_LockIndicatorFb_BCM_LockIndicatorFb: accessed-variable=BCM_LockIndicatorFb.BCM_LockIndicatorFb
              SendPoint_BCM_ChrgnFlapLeClsSt_BCM_ChrgnFlapLeClsSt: accessed-variable=BCM_ChrgnFlapLeClsSt.BCM_ChrgnFlapLeClsSt
              SendPoint_BCM_ChrgnFlapRiClsSt_BCM_ChrgnFlapRiClsSt: accessed-variable=BCM_ChrgnFlapRiClsSt.BCM_ChrgnFlapRiClsSt
              SendPoint_BCM_EclBeReqToTagetPos_BCM_EclBeReqToTagetPos: accessed-variable=BCM_EclBeReqToTagetPos.BCM_EclBeReqToTagetPos
              SendPoint_PEtrunk_PEtrunk: accessed-variable=PEtrunk.PEtrunk
              SendPoint_BCM_TrOpenerReqTrigSrc_BCM_TrOpenerReqTrigSrc: accessed-variable=BCM_TrOpenerReqTrigSrc.BCM_TrOpenerReqTrigSrc
              SendPoint_BCM_ElecTrOpenCls_BCM_ElecTrOpenCls: accessed-variable=BCM_ElecTrOpenCls.BCM_ElecTrOpenCls
              SendPoint_BCM_KickSensorEnablerCmd_BCM_KickSensorEnablerCmd: accessed-variable=BCM_KickSensorEnablerCmd.BCM_KickSensorEnablerCmd
              SendPoint_WarningFromLock_WarningFromLock: accessed-variable=WarningFromLock.WarningFromLock
              SendPoint_BCM_ChrgnFlapRiNotClsdWarnReq_BCM_ChrgnFlapRiNotClsdWarnReq: accessed-variable=BCM_ChrgnFlapRiNotClsdWarnReq.BCM_ChrgnFlapRiNotClsdWarnReq
              SendPoint_BCM_BLELocalizationReq_BCM_BLELocalizationReq: accessed-variable=BCM_BLELocalizationReq.BCM_BLELocalizationReq
              SendPoint_Pskeyincar_Pskeyincar: accessed-variable=Pskeyincar.Pskeyincar
              SendPoint_CentralDoorLockLIN8WkpReq_CentralDoorLockLIN8WkpReq: accessed-variable=CentralDoorLockLIN8WkpReq.CentralDoorLockLIN8WkpReq
          sync call SynchSrvCallPoint_Event_EV_DTC_E11F87_SetEventStatus: operation=Event_EV_DTC_E11F87.SetEventStatus, timeout=0.0
        CentralDoorLock_DataServices_DID_AA30_Data_ReadData: symbol=sym_CentralDoorLock_DataServices_DID_AA30_Data_ReadData
        CentralDoorLock_DataServices_DID_AA30_Data_ShortTermAdjustment: symbol=sym_CentralDoorLock_DataServices_DID_AA30_Data_ShortTermAdjustment
        CentralDoorLock_DataServices_DID_AA30_Data_ConditionCheckRead: symbol=sym_CentralDoorLock_DataServices_DID_AA30_Data_ConditionCheckRead
        CentralDoorLock_DataServices_DID_AA30_Data_ReturnControlToECU: symbol=sym_CentralDoorLock_DataServices_DID_AA30_Data_ReturnControlToECU
        CentralDoorLock_DataServices_DID_AA22_Data_ReadData: symbol=sym_CentralDoorLock_DataServices_DID_AA22_Data_ReadData
        CentralDoorLock_DataServices_DID_AA22_Data_ShortTermAdjustment: symbol=sym_CentralDoorLock_DataServices_DID_AA22_Data_ShortTermAdjustment
        CentralDoorLock_DataServices_DID_AA22_Data_ConditionCheckRead: symbol=sym_CentralDoorLock_DataServices_DID_AA22_Data_ConditionCheckRead
        CentralDoorLock_DataServices_DID_AA22_Data_ReturnControlToECU: symbol=sym_CentralDoorLock_DataServices_DID_AA22_Data_ReturnControlToECU
        CentralDoorLock_DataServices_DID_AAIE_Data_ReadData: symbol=sym_CentralDoorLock_DataServices_DID_AAIE_Data_ReadData
        CentralDoorLock_DataServices_DID_AA1E_Data_ShortTermAdjustment: symbol=sym_CentralDoorLock_DataServices_DID_AA1E_Data_ShortTermAdjustment
        CentralDoorLock_DataServices_DID_AA1E_Data_ConditionCheckRead: symbol=sym_CentralDoorLock_DataServices_DID_AA1E_Data_ConditionCheckRead
        CentralDoorLock_DataServices_DID_AA1E_Data_ReturnControlToECU: symbol=sym_CentralDoorLock_DataServices_DID_AA1E_Data_ReturnControlToECU
        CentralDoorLock_DataServices_DID_AA1E_Data_ReadData: symbol=sym_CentralDoorLock_DataServices_DID_AA1E_Data_ReadData
      swc service dependency Swc_CentralDoorLockNvAlias
        assigned-datas:
          role=ramBlock, used-data-element=CentralDoorLockNvAlias
          role=defaultValue, used-parameter-element=CentralDoorLockNvInit
        service-needs:
          nv block needs NVMServiceNeeds: calc-ram-block-crc=true, n-data-sets=0, n-rom-blocks=0, reliability=ERROR-CORRECTION, restore-at-start=true, store-at-shutdown=true, writing-frequency=3650, writing-priority=MEDIUM
      shared-parameters:
        parameter data prototype CentralDoorLockNvInit: type=CentralDoorLockNvStruct, init-value=constant-reference=CentralDoorLockNvInit
  swc implementation ImplCentralDoorLock: programming-language=C, sw-version=4.0.2, used-code-generator=hand coded, vendor-id=41, behavior=IBCentralDoorLock
    code-descriptors:
      code Code: artifact-descriptors=autosar-engineering-object={short-label=dummy_c, category=dummy}
    resource consumption ResConsumption1
      80 x memory section:
        VAR_INIT_8: alignment=8, sw-addrmethod=VAR_INIT
        VAR_INIT_16: alignment=16, sw-addrmethod=VAR_INIT
        VAR_INIT_32: alignment=32, sw-addrmethod=VAR_INIT
        VAR_INIT_BOOLEAN: alignment=BOOLEAN, sw-addrmethod=VAR_INIT
        VAR_INIT_UNSPECIFIED: alignment=UNSPECIFIED, sw-addrmethod=VAR_INIT
        VAR_NO_INIT_16: alignment=16, sw-addrmethod=VAR_NO_INIT
        VAR_NO_INIT_32: alignment=32, sw-addrmethod=VAR_NO_INIT
        VAR_NO_INIT_8: alignment=8, sw-addrmethod=VAR_NO_INIT
        VAR_NO_INIT_BOOLEAN: alignment=BOOLEAN, sw-addrmethod=VAR_NO_INIT
        VAR_NO_INIT_UNSPECIFIED: alignment=UNSPECIFIED, sw-addrmethod=VAR_NO_INIT
        VAR_CLEARED_8: alignment=8, sw-addrmethod=VAR_CLEARED
        VAR_CLEARED_UNSPECIFIED: alignment=UNSPECIFIED, sw-addrmethod=VAR_CLEARED
        VAR_POWER_ON_CLEARED_32: alignment=32, sw-addrmethod=VAR_POWER_ON_CLEARED
        POSTBUILD_VAR_NO_INIT_16: alignment=16, sw-addrmethod=POSTBUILD_VAR_NO_INIT
        POSTBUILD_VAR_NO_INIT_32: alignment=32, sw-addrmethod=POSTBUILD_VAR_NO_INIT
        POSTBUILD_VAR_NO_INIT_8: alignment=8, sw-addrmethod=POSTBUILD_VAR_NO_INIT
        POSTBUILD_VAR_NO_INIT_BOOLEAN: alignment=BOOLEAN, sw-addrmethod=POSTBUILD_VAR_NO_INIT
        POSTBUILD_VAR_NO_INIT_UNSPECIFIED: alignment=UNSPECIFIED, sw-addrmethod=POSTBUILD_VAR_NO_INIT
        CONST_16: alignment=16, sw-addrmethod=CONST
        CONST_32: alignment=32, sw-addrmethod=CONST
        CONST_8: alignment=8, sw-addrmethod=CONST
        CONST_UNSPECIFIED: alignment=UNSPECIFIED, sw-addrmethod=CONST
        CONFIG_DATA_16: alignment=16, sw-addrmethod=CONFIG_DATA
        CONFIG_DATA_32: alignment=32, sw-addrmethod=CONFIG_DATA
        CONFIG_DATA_8: alignment=8, sw-addrmethod=CONFIG_DATA
        CONFIG_DATA_UNSPECIFIED: alignment=UNSPECIFIED, sw-addrmethod=CONFIG_DATA
        POSTBUILD_CONST_16: alignment=16, sw-addrmethod=POSTBUILD_CONST
        POSTBUILD_CONST_32: alignment=32, sw-addrmethod=POSTBUILD_CONST
        POSTBUILD_CONST_8: alignment=8, sw-addrmethod=POSTBUILD_CONST
        POSTBUILD_CONST_UNSPECIFIED: alignment=UNSPECIFIED, sw-addrmethod=POSTBUILD_CONST
        CALIB_16: alignment=16, sw-addrmethod=CALIB
        CALIB_32: alignment=32, sw-addrmethod=CALIB
        CALIB_8: alignment=8, sw-addrmethod=CALIB
        CALIB_UNSPECIFIED: alignment=UNSPECIFIED, sw-addrmethod=CALIB
        CODE: alignment=UNSPECIFIED, sw-addrmethod=CODE
        CALLOUT_CODE: alignment=UNSPECIFIED, sw-addrmethod=CALLOUT_CODE
        APTIV_NOAPPLINIT_SECURE_UNSPECIFIED: alignment=UNSPECIFIED, sw-addrmethod=APTIV_NOAPPLINIT_SECURE
        APTIV_DISP: alignment=UNSPECIFIED, sw-addrmethod=APTIV_DISP
        APTIV_RUN: alignment=UNSPECIFIED, sw-addrmethod=APTIV_RUN
        LOCAL_CONFIG: alignment=UNSPECIFIED, sw-addrmethod=CONFIG_DATA
        VAR_INIT_8: alignment=8, sw-addrmethod=VAR_INIT
        VAR_INIT_16: alignment=16, sw-addrmethod=VAR_INIT
        VAR_INIT_32: alignment=32, sw-addrmethod=VAR_INIT
        VAR_INIT_BOOLEAN: alignment=BOOLEAN, sw-addrmethod=VAR_INIT
        VAR_INIT_UNSPECIFIED: alignment=UNSPECIFIED, sw-addrmethod=VAR_INIT
        VAR_NO_INIT_16: alignment=16, sw-addrmethod=VAR_NO_INIT
        VAR_NO_INIT_32: alignment=32, sw-addrmethod=VAR_NO_INIT
        VAR_NO_INIT_8: alignment=8, sw-addrmethod=VAR_NO_INIT
        VAR_NO_INIT_BOOLEAN: alignment=BOOLEAN, sw-addrmethod=VAR_NO_INIT
        VAR_NO_INIT_UNSPECIFIED: alignment=UNSPECIFIED, sw-addrmethod=VAR_NO_INIT
        VAR_CLEARED_8: alignment=8, sw-addrmethod=VAR_CLEARED
        VAR_CLEARED_UNSPECIFIED: alignment=UNSPECIFIED, sw-addrmethod=VAR_CLEARED
        VAR_POWER_ON_CLEARED_32: alignment=32, sw-addrmethod=VAR_POWER_ON_CLEARED
        POSTBUILD_VAR_NO_INIT_16: alignment=16, sw-addrmethod=POSTBUILD_VAR_NO_INIT
        POSTBUILD_VAR_NO_INIT_32: alignment=32, sw-addrmethod=POSTBUILD_VAR_NO_INIT
        POSTBUILD_VAR_NO_INIT_8: alignment=8, sw-addrmethod=POSTBUILD_VAR_NO_INIT
        POSTBUILD_VAR_NO_INIT_BOOLEAN: alignment=BOOLEAN, sw-addrmethod=POSTBUILD_VAR_NO_INIT
        POSTBUILD_VAR_NO_INIT_UNSPECIFIED: alignment=UNSPECIFIED, sw-addrmethod=POSTBUILD_VAR_NO_INIT
        CONST_16: alignment=16, sw-addrmethod=CONST
        CONST_32: alignment=32, sw-addrmethod=CONST
        CONST_8: alignment=8, sw-addrmethod=CONST
        CONST_UNSPECIFIED: alignment=UNSPECIFIED, sw-addrmethod=CONST
        CONFIG_DATA_16: alignment=16, sw-addrmethod=CONFIG_DATA
        CONFIG_DATA_32: alignment=32, sw-addrmethod=CONFIG_DATA
        CONFIG_DATA_8: alignment=8, sw-addrmethod=CONFIG_DATA
        CONFIG_DATA_UNSPECIFIED: alignment=UNSPECIFIED, sw-addrmethod=CONFIG_DATA
        POSTBUILD_CONST_16: alignment=16, sw-addrmethod=POSTBUILD_CONST
        POSTBUILD_CONST_32: alignment=32, sw-addrmethod=POSTBUILD_CONST
        POSTBUILD_CONST_8: alignment=8, sw-addrmethod=POSTBUILD_CONST
        POSTBUILD_CONST_UNSPECIFIED: alignment=UNSPECIFIED, sw-addrmethod=POSTBUILD_CONST
        CALIB_16: alignment=16, sw-addrmethod=CALIB
        CALIB_32: alignment=32, sw-addrmethod=CALIB
        CALIB_8: alignment=8, sw-addrmethod=CALIB
        CALIB_UNSPECIFIED: alignment=UNSPECIFIED, sw-addrmethod=CALIB
        CODE: alignment=UNSPECIFIED, sw-addrmethod=CODE
        CALLOUT_CODE: alignment=UNSPECIFIED, sw-addrmethod=CALLOUT_CODE
        APTIV_NOAPPLINIT_SECURE: alignment=UNSPECIFIED, sw-addrmethod=APTIV_NOAPPLINIT_SECURE
        APTIV_DISP: alignment=UNSPECIFIED, sw-addrmethod=APTIV_DISP
        APTIV_RUN: alignment=UNSPECIFIED, sw-addrmethod=APTIV_RUN
        LOCAL_CONFIG: alignment=UNSPECIFIED, sw-addrmethod=CONFIG_DATA
package /APTIV_MODEL_APP/Calibration/CentralDoorLock
  constant specification CentralDoorLockNvInit: value-spec=fields=[0, 0, 0, 0, 0, 0, 0, 0, 0]
